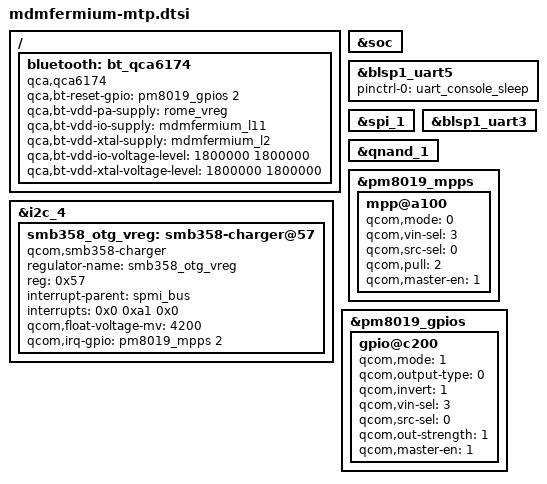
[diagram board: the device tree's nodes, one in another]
/*
 * Copyright (c) 2015, The Linux Foundation. All rights reserved.
 *
 * This program is free software; you can redistribute it and/or modify
 * it under the terms of the GNU General Public License version 2 and
 * only version 2 as published by the Free Software Foundation.
 *
 * This program is distributed in the hope that it will be useful,
 * but WITHOUT ANY WARRANTY; without even the implied warranty of
 * MERCHANTABILITY or FITNESS FOR A PARTICULAR PURPOSE.  See the
 * GNU General Public License for more details.
 */

#include "mdmfermium.dtsi"
#include "mdmfermium-pinctrl.dtsi"

/ {
	bluetooth: bt_qca6174 {
		compatible = "qca,qca6174";
		qca,bt-reset-gpio = <&pm8019_gpios 2 0>; /* BT_EN */
		qca,bt-vdd-pa-supply = <&rome_vreg>;
		qca,bt-vdd-io-supply = <&mdmfermium_l11>;
		qca,bt-vdd-xtal-supply = <&mdmfermium_l2>;
		qca,bt-vdd-io-voltage-level = <1800000 1800000>;
		qca,bt-vdd-xtal-voltage-level = <1800000 1800000>;
	};
};

&soc {
};

&blsp1_uart5 {
	status = "ok";
	pinctrl-names = "default";
	pinctrl-0 = <&uart_console_sleep>;
};

&i2c_4 {
	status = "ok";
};

&spi_1 {
	status = "ok";
};

&blsp1_uart3 {
	status = "ok";
};

&qnand_1 {
	status = "ok";
};

/* MPP pin 2 configs for SMB358 interrupt line */
&pm8019_mpps {
	mpp@a100 {
		qcom,mode = <0>;	/* Digital input */
		qcom,vin-sel = <3>;	/* 1.8V (L11) */
		qcom,src-sel = <0>;	/* QPNP_PIN_SEL_FUNC_CONSTANT */
		qcom,pull = <2>;	/* PULL UP 10KOHM */
		qcom,master-en = <1>;
	};
};

/* PMIC gpio for wlan power supply */
&pm8019_gpios {
	gpio@c200 {
		qcom,mode = <1>;		/* Digital output */
		qcom,output-type = <0>;		/* CMOS logic */
		qcom,invert = <1>;		/* Output high */
		qcom,vin-sel = <3>;		/* VPH_PWR */
		qcom,src-sel = <0>;		/* Constant */
		qcom,out-strength = <1>;	/* High drive strength */
		qcom,master-en = <1>;		/* Enable GPIO */
		status = "okay";
	};
};

&i2c_4 {
	/* SMB358 charger configuration */
	smb358_otg_vreg: smb358-charger@57 {
		compatible = "qcom,smb358-charger";
		regulator-name = "smb358_otg_vreg";
		reg = <0x57>;
		interrupt-parent = <&spmi_bus>;
		interrupts = <0x0 0xa1 0x0>;	/* PMIC MPP 2 */
		qcom,float-voltage-mv = <4200>;
		qcom,irq-gpio = <&pm8019_mpps 2 0>;
	};
};
